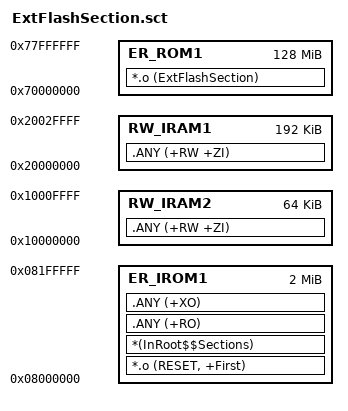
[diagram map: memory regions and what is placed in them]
; *************************************************************
; *** Scatter-Loading Description File generated by uVision ***
; *************************************************************

LR_IROM1 0x08000000 0x00200000  {    ; load region size_region
  ER_IROM1 0x08000000 0x00200000  {  ; load address = execution address
   *.o (RESET, +First)
   *(InRoot$$Sections)
   .ANY (+RO)
   .ANY (+XO)
  }
  RW_IRAM1 0x20000000 0x00030000  {  ; RW data
   .ANY (+RW +ZI)
  }
  RW_IRAM2 0x10000000 0x00010000  {
   .ANY (+RW +ZI)
  }
}

LR_ROM1 0x70000000 0x08000000  {
  ER_ROM1 0x70000000 0x08000000  {  ; load address = execution address
   ;*.o (FontFlashSection)
   ;*.o (FontSearchFlashSection)
   ;*.o (TextFlashSection)
   *.o (ExtFlashSection)
  }
}

